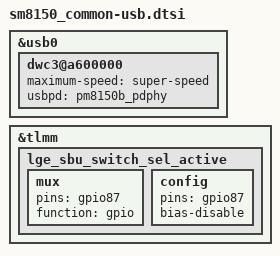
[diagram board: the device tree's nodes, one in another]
// SPDX-License-Identifier: GPL-2.0

&usb0 {
	dwc3@a600000 {
		maximum-speed = "super-speed";
		usbpd = <&pm8150b_pdphy>;
	};
};

&tlmm {
	lge_sbu_switch_sel_active: lge_sbu_switch_sel_active {
		mux {
			pins = "gpio87";
			function = "gpio";
		};

		config {
			pins = "gpio87";
			bias-disable;
		};
	};
};
